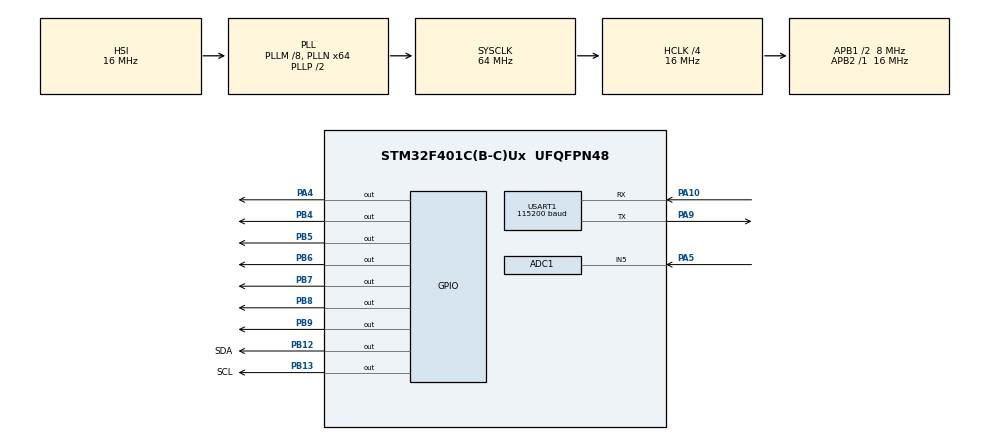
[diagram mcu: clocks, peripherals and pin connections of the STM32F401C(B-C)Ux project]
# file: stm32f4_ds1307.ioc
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ADC1.Channel-1\#ChannelRegularConversion=ADC_CHANNEL_5
ADC1.ContinuousConvMode=ENABLE
ADC1.NbrOfConversion=1
ADC1.NbrOfConversionFlag=1
ADC1.Rank-1\#ChannelRegularConversion=1
ADC1.SamplingTime-1\#ChannelRegularConversion=ADC_SAMPLETIME_3CYCLES
ADC1.ScanConvMode=ENABLE
ADC1.master=1
Dma.ADC1.0.Direction=DMA_PERIPH_TO_MEMORY
Dma.ADC1.0.FIFOMode=DMA_FIFOMODE_DISABLE
Dma.ADC1.0.Instance=DMA2_Stream0
Dma.ADC1.0.MemDataAlignment=DMA_MDATAALIGN_HALFWORD
Dma.ADC1.0.MemInc=DMA_MINC_ENABLE
Dma.ADC1.0.Mode=DMA_CIRCULAR
Dma.ADC1.0.PeriphDataAlignment=DMA_PDATAALIGN_HALFWORD
Dma.ADC1.0.PeriphInc=DMA_PINC_DISABLE
Dma.ADC1.0.Priority=DMA_PRIORITY_LOW
Dma.Request0=ADC1
Mcu.Family=STM32F4
Mcu.Name=STM32F401C(B-C)Ux
Mcu.Package=UFQFPN48
NVIC.DMA2_Stream0_IRQn=true\:0\:0\:false\:false\:true\:false\:true\:true
NVIC.PriorityGroup=NVIC_PRIORITYGROUP_4
NVIC.USART1_IRQn=true\:0\:0\:false\:false\:true\:true\:true\:true
PA10.Mode=Asynchronous
PA10.Signal=USART1_RX
PA4.GPIO_ModeDefaultOutputPP=GPIO_MODE_OUTPUT_OD
PA4.GPIO_PuPd=GPIO_PULLUP
PA4.GPIO_Speed=GPIO_SPEED_FREQ_LOW
PA4.Signal=GPIO_Output
PA5.Signal=ADCx_IN5
PA9.Mode=Asynchronous
PA9.Signal=USART1_TX
PB12.GPIO_Label=SDA
PB12.GPIO_ModeDefaultOutputPP=GPIO_MODE_OUTPUT_OD
PB12.GPIO_PuPd=GPIO_PULLUP
PB12.Signal=GPIO_Output
PB13.GPIO_Label=SCL
PB13.GPIO_PuPd=GPIO_PULLUP
PB13.Signal=GPIO_Output
PB4.Signal=GPIO_Output
PB5.Signal=GPIO_Output
PB6.Signal=GPIO_Output
PB7.Signal=GPIO_Output
PB8.Signal=GPIO_Output
PB9.Signal=GPIO_Output
PH0\ -\ OSC_IN.Mode=HSE-External-Oscillator
PH0\ -\ OSC_IN.Signal=RCC_OSC_IN
PH1\ -\ OSC_OUT.Mode=HSE-External-Oscillator
PH1\ -\ OSC_OUT.Signal=RCC_OSC_OUT
ProjectManager.HeapSize=0x200
ProjectManager.StackSize=0x400
ProjectManager.TargetToolchain=STM32CubeIDE
RCC.48MHZClocksFreq_Value=32000000
RCC.AHBCLKDivider=RCC_SYSCLK_DIV4
RCC.AHBFreq_Value=16000000
RCC.APB1CLKDivider=RCC_HCLK_DIV2
RCC.APB1Freq_Value=8000000
RCC.APB1TimFreq_Value=16000000
RCC.APB2Freq_Value=16000000
RCC.APB2TimFreq_Value=16000000
RCC.CortexFreq_Value=16000000
RCC.HCLKFreq_Value=16000000
RCC.HSE_VALUE=25000000
RCC.HSI_VALUE=16000000
RCC.LSE_VALUE=32768
RCC.PLLM=8
RCC.PLLN=64
RCC.SYSCLKFreq_VALUE=64000000
RCC.SYSCLKSource=RCC_SYSCLKSOURCE_PLLCLK
RCC.VCOOutputFreq_Value=128000000
SH.ADCx_IN5.0=ADC1_IN5,IN5
TIM1.Prescaler=15
USART1.BaudRate=115200
USART1.VirtualMode=VM_ASYNC
VP_TIM1_VS_ClockSourceINT.Mode=Internal
board=custom

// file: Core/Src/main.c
/* USER CODE BEGIN Header */
/**
  ******************************************************************************
  * @file           : main.c
  * @brief          : Main program body
  * @author         : Metehan Yenil
  * @linkedin       : https://www.linkedin.com/in/metehanyenil/
  * @github         : https://github.com/Metehan-Yenil
  ******************************************************************************
  * @attention
  *
  * Copyright (c) 2025 STMicroelectronics.
  * All rights reserved.
  *
  * This software is licensed under terms that can be found in the LICENSE file
  * in the root directory of this software component.
  * If no LICENSE file comes with this software, it is provided AS-IS.
  *
  ******************************************************************************
  */
/* USER CODE END Header */
#include "main.h"

/* USER CODE BEGIN Includes */
#include "lcd.h"
#include "ds1307.h"
#include <stdio.h>
#include <time.h>
#include <stdlib.h>  // atoi için
#include <string.h>
#include "ntc.h"
#include "ntcConfig.h"
#include "dht.h"
#include "delay.h"
/* USER CODE END Includes */

/* USER CODE BEGIN PD */
#define MAX_BUFFER_SIZE 13
/* USER CODE END PD */

ADC_HandleTypeDef hadc1;
DMA_HandleTypeDef hdma_adc1;

TIM_HandleTypeDef htim1;

UART_HandleTypeDef huart1;

/* USER CODE BEGIN PV */
uint8_t txdata[14];
uint8_t rxdata[14];
uint8_t sn,dak,saat,gun,haftagun,ay,yil;
uint16_t x=0;
uint16_t y=0;
uint8_t dataIndex = 0;
uint32_t adcData[1]; // ADC verileri için bir değişken tanımı
char uartBuffer[MAX_BUFFER_SIZE];  // UART'tan alınan veri burada saklanır
volatile uint8_t uartIndex = 0;    // UART veri indeksini takip eder
volatile uint8_t veriTamamlandi = 0; // Verinin tamamlandığını işaretler
float temperature,humidity;
uint16_t tiksay=0;
char transmitBuffer[5];
float sicaklik;

/* USER CODE END PV */

void SystemClock_Config(void);
static void MX_GPIO_Init(void);
static void MX_DMA_Init(void);
static void MX_TIM1_Init(void);
static void MX_USART1_UART_Init(void);
static void MX_ADC1_Init(void);

/* USER CODE BEGIN 0 */

void delay_us (uint16_t delay)
{
  __HAL_TIM_SET_COUNTER(&htim1, 0);
  while (__HAL_TIM_GET_COUNTER(&htim1) < delay);
}

void HAL_UART_ErrorCallback(UART_HandleTypeDef *huart) {
    if (huart->Instance == USART1) {
        clearLcd();
        writeStr(1,0,"UART Hatasi!");
        HAL_Delay(1000);

        dataIndex = 0;  // Buffer'ı sıfırla
        HAL_UART_Receive_IT(&huart1, rxdata, 1);
    }
}

void veriyiIsle()
{
    if (veriTamamlandi)
    {
        // Gelen veri formatı: "ddMMyyHHmmss"
        char tempBuffer[5]; // Geçici buffer

        // Gün
        strncpy(tempBuffer, uartBuffer, 2);
        tempBuffer[2] = '\0'; // Sonlandırıcı ekle
        gun = atoi(tempBuffer);

        // Ay
        strncpy(tempBuffer, uartBuffer + 2, 2);
        tempBuffer[2] = '\0';
        ay = atoi(tempBuffer);

        // Yıl
        strncpy(tempBuffer, uartBuffer + 4, 2);
        tempBuffer[2] = '\0';
        yil = atoi(tempBuffer);

        // Saat
        strncpy(tempBuffer, uartBuffer + 6, 2);
        tempBuffer[2] = '\0';
        saat = atoi(tempBuffer);

        // Dakika
        strncpy(tempBuffer, uartBuffer + 8, 2);
        tempBuffer[2] = '\0';
        dak = atoi(tempBuffer);

        // Saniye
        strncpy(tempBuffer, uartBuffer + 10, 2);
        tempBuffer[2] = '\0';
        sn = atoi(tempBuffer);

        SetDateTime_ds1307();

        clearLcd();
        y=veriTamamlandi;
        veriTamamlandi = 0;

    }
}

void FormatAndSendData(void) {

    char Txbuffer[24]; 					// Gönderilecek veri için buffer
    HAL_StatusTypeDef status;

    GetDateTime_ds1307();
    DHT_GetData(); 						// DHT22 sıcaklık ve nem bilgisi al

    snprintf(Txbuffer, sizeof(Txbuffer), "<%.2f %.2f %.2f %02d:%02d:%02d %02d;%02d;%02d>",
    		 sicaklik, 	  // NTC Sıcaklık
			 temperature,        // DHT sıcaklık
             humidity,          // DHT nem
             saat,        // Saat
             dak,    // Dakika
             sn,   // Saniye
             gun,      // Gün
             ay,   // Ay
             yil);  // Yıl

    status = HAL_UART_Transmit(&huart1, (uint8_t*)Txbuffer, strlen(Txbuffer), 100);
    if (status != HAL_OK) {

        char error_msg[] = "USART transmit error!\r\n";
        HAL_UART_Transmit(&huart1, (uint8_t*)error_msg, strlen(error_msg), 100);
        clearLcd();
        writeStr(1,0,"transmit error");
        HAL_Delay(2000);
    }
}

/* USER CODE END 0 */

int main(void)
{

  /* MCU Configuration--------------------------------------------------------*/

  /* Reset of all peripherals, Initializes the Flash interface and the Systick. */
  HAL_Init();

  /* Configure the system clock */
  SystemClock_Config();

  /* Initialize all configured peripherals */
  MX_GPIO_Init();
  MX_DMA_Init();
  MX_TIM1_Init();
  MX_USART1_UART_Init();
  MX_ADC1_Init();
  /* USER CODE BEGIN 2 */
      HAL_TIM_Base_Start(&htim1);

       lcdInit();
       writeStr(1,0,"SISTEM          ");
       writeStr(2,0,"BASLIYOR        ");
       HAL_Delay(2000);
       clearLcd();
       //HAL_UART_Receive_IT(&huart1, rxdata, 1);
                  if(HAL_UART_Receive_IT(&huart1, rxdata, 1) != HAL_OK)
                  {
                      writeStr(1,0,"UART Hata!");
                      HAL_Delay(1000);

                  }
                  else
                  {
                      writeStr(1,0,"UART Hazir");
                      writeStr(2,0,"Veri Bekliyor");
                      HAL_Delay(1000);
                      clearLcd();
                  }

       //saat=01; dak=59; sn=55;
      //SetDateTime_ds1307();
  /* USER CODE END 2 */

  /* Infinite loop */
  /* USER CODE BEGIN WHILE */
  while (1)
  {
	  if(tiksay>=2000){
	  		  tiksay=0;
	  		  DHT_GetData();
	  	  	  writeStr(2,9,"rh");
	  	  	  displayFloat(2,11, humidity);
	  	  	  writeStr(2,13,"T");
	  	  	  displayFloat(2, 14,temperature);

	  }
    HAL_ADC_Start_DMA(&hadc1, (uint32_t*)adcData, 1);

    veriyiIsle();
    GetDateTime_ds1307();
    displayInt(1,0,saat);
    writeStr(1,2,":");
    displayInt(1,3,dak);
    writeStr(1,5,":");
    displayInt(1,6,sn);

    displayInt(2,0,gun);
    writeStr(2,2,"/");
    displayInt(2,3,ay);
    writeStr(2,5,"/");
    displayInt(2,6,yil);
    writeStr(1,9,"A:");displayInt(1,11,ntc_convertToC(adcData[0]));writeStr(1,13,"C");

    	sicaklik = ntc_convertToC(adcData[0]);
       /* sprintf(transmitBuffer, "%d\n", sicaklik);
        HAL_UART_Transmit(&huart1, (uint8_t*)transmitBuffer, strlen(transmitBuffer), 100);
    delay_us(1000);
    x++;*/
    FormatAndSendData();
    //HAL_Delay(1000);
    /* USER CODE END WHILE */

  }
}

void SystemClock_Config(void)
{
  RCC_OscInitTypeDef RCC_OscInitStruct = {0};
  RCC_ClkInitTypeDef RCC_ClkInitStruct = {0};

  /** Configure the main internal regulator output voltage
  */
  __HAL_RCC_PWR_CLK_ENABLE();
  __HAL_PWR_VOLTAGESCALING_CONFIG(PWR_REGULATOR_VOLTAGE_SCALE2);

  /** Initializes the RCC Oscillators according to the specified parameters
  * in the RCC_OscInitTypeDef structure.
  */
  RCC_OscInitStruct.OscillatorType = RCC_OSCILLATORTYPE_HSI;
  RCC_OscInitStruct.HSIState = RCC_HSI_ON;
  RCC_OscInitStruct.HSICalibrationValue = RCC_HSICALIBRATION_DEFAULT;
  RCC_OscInitStruct.PLL.PLLState = RCC_PLL_ON;
  RCC_OscInitStruct.PLL.PLLSource = RCC_PLLSOURCE_HSI;
  RCC_OscInitStruct.PLL.PLLM = 8;
  RCC_OscInitStruct.PLL.PLLN = 64;
  RCC_OscInitStruct.PLL.PLLP = RCC_PLLP_DIV2;
  RCC_OscInitStruct.PLL.PLLQ = 4;
  if (HAL_RCC_OscConfig(&RCC_OscInitStruct) != HAL_OK)
  {
    Error_Handler();
  }

  /** Initializes the CPU, AHB and APB buses clocks
  */
  RCC_ClkInitStruct.ClockType = RCC_CLOCKTYPE_HCLK|RCC_CLOCKTYPE_SYSCLK
                              |RCC_CLOCKTYPE_PCLK1|RCC_CLOCKTYPE_PCLK2;
  RCC_ClkInitStruct.SYSCLKSource = RCC_SYSCLKSOURCE_PLLCLK;
  RCC_ClkInitStruct.AHBCLKDivider = RCC_SYSCLK_DIV4;
  RCC_ClkInitStruct.APB1CLKDivider = RCC_HCLK_DIV2;
  RCC_ClkInitStruct.APB2CLKDivider = RCC_HCLK_DIV1;

  if (HAL_RCC_ClockConfig(&RCC_ClkInitStruct, FLASH_LATENCY_0) != HAL_OK)
  {
    Error_Handler();
  }
}

static void MX_ADC1_Init(void)
{

  ADC_ChannelConfTypeDef sConfig = {0};

  /** Configure the global features of the ADC (Clock, Resolution, Data Alignment and number of conversion)
  */
  hadc1.Instance = ADC1;
  hadc1.Init.ClockPrescaler = ADC_CLOCK_SYNC_PCLK_DIV2;
  hadc1.Init.Resolution = ADC_RESOLUTION_12B;
  hadc1.Init.ScanConvMode = ENABLE;
  hadc1.Init.ContinuousConvMode = ENABLE;
  hadc1.Init.DiscontinuousConvMode = DISABLE;
  hadc1.Init.ExternalTrigConvEdge = ADC_EXTERNALTRIGCONVEDGE_NONE;
  hadc1.Init.ExternalTrigConv = ADC_SOFTWARE_START;
  hadc1.Init.DataAlign = ADC_DATAALIGN_RIGHT;
  hadc1.Init.NbrOfConversion = 1;
  hadc1.Init.DMAContinuousRequests = DISABLE;
  hadc1.Init.EOCSelection = ADC_EOC_SINGLE_CONV;
  if (HAL_ADC_Init(&hadc1) != HAL_OK)
  {
    Error_Handler();
  }

  /** Configure for the selected ADC regular channel its corresponding rank in the sequencer and its sample time.
  */
  sConfig.Channel = ADC_CHANNEL_5;
  sConfig.Rank = 1;
  sConfig.SamplingTime = ADC_SAMPLETIME_3CYCLES;
  if (HAL_ADC_ConfigChannel(&hadc1, &sConfig) != HAL_OK)
  {
    Error_Handler();
  }

}

static void MX_TIM1_Init(void)
{

  TIM_ClockConfigTypeDef sClockSourceConfig = {0};
  TIM_MasterConfigTypeDef sMasterConfig = {0};

  htim1.Instance = TIM1;
  htim1.Init.Prescaler = 15;
  htim1.Init.CounterMode = TIM_COUNTERMODE_UP;
  htim1.Init.Period = 65535;
  htim1.Init.ClockDivision = TIM_CLOCKDIVISION_DIV1;
  htim1.Init.RepetitionCounter = 0;
  htim1.Init.AutoReloadPreload = TIM_AUTORELOAD_PRELOAD_DISABLE;
  if (HAL_TIM_Base_Init(&htim1) != HAL_OK)
  {
    Error_Handler();
  }
  sClockSourceConfig.ClockSource = TIM_CLOCKSOURCE_INTERNAL;
  if (HAL_TIM_ConfigClockSource(&htim1, &sClockSourceConfig) != HAL_OK)
  {
    Error_Handler();
  }
  sMasterConfig.MasterOutputTrigger = TIM_TRGO_RESET;
  sMasterConfig.MasterSlaveMode = TIM_MASTERSLAVEMODE_DISABLE;
  if (HAL_TIMEx_MasterConfigSynchronization(&htim1, &sMasterConfig) != HAL_OK)
  {
    Error_Handler();
  }

}

static void MX_USART1_UART_Init(void)
{

  huart1.Instance = USART1;
  huart1.Init.BaudRate = 9600;
  huart1.Init.WordLength = UART_WORDLENGTH_8B;
  huart1.Init.StopBits = UART_STOPBITS_1;
  huart1.Init.Parity = UART_PARITY_NONE;
  huart1.Init.Mode = UART_MODE_TX_RX;
  huart1.Init.HwFlowCtl = UART_HWCONTROL_NONE;
  huart1.Init.OverSampling = UART_OVERSAMPLING_16;
  if (HAL_UART_Init(&huart1) != HAL_OK)
  {
    Error_Handler();
  }

}

static void MX_DMA_Init(void)
{

  /* DMA controller clock enable */
  __HAL_RCC_DMA2_CLK_ENABLE();

  /* DMA interrupt init */
  /* DMA2_Stream0_IRQn interrupt configuration */
  HAL_NVIC_SetPriority(DMA2_Stream0_IRQn, 0, 0);
  HAL_NVIC_EnableIRQ(DMA2_Stream0_IRQn);

}

static void MX_GPIO_Init(void)
{
  GPIO_InitTypeDef GPIO_InitStruct = {0};

  /* GPIO Ports Clock Enable */
  __HAL_RCC_GPIOH_CLK_ENABLE();
  __HAL_RCC_GPIOA_CLK_ENABLE();
  __HAL_RCC_GPIOB_CLK_ENABLE();

  /*Configure GPIO pin Output Level */
  HAL_GPIO_WritePin(GPIOA, GPIO_PIN_4, GPIO_PIN_RESET);

  /*Configure GPIO pin Output Level */
  HAL_GPIO_WritePin(GPIOB, GPIO_PIN_10|SDA_Pin|SCL_Pin|GPIO_PIN_4
                          |GPIO_PIN_5|GPIO_PIN_6|GPIO_PIN_7|GPIO_PIN_8
                          |GPIO_PIN_9, GPIO_PIN_RESET);

  /*Configure GPIO pin : PA4 */
  GPIO_InitStruct.Pin = GPIO_PIN_4;
  GPIO_InitStruct.Mode = GPIO_MODE_OUTPUT_OD;
  GPIO_InitStruct.Pull = GPIO_PULLUP;
  GPIO_InitStruct.Speed = GPIO_SPEED_FREQ_LOW;
  HAL_GPIO_Init(GPIOA, &GPIO_InitStruct);

  /*Configure GPIO pins : PB10 PB4 PB5 PB6
                           PB7 PB8 PB9 */
  GPIO_InitStruct.Pin = GPIO_PIN_10|GPIO_PIN_4|GPIO_PIN_5|GPIO_PIN_6
                          |GPIO_PIN_7|GPIO_PIN_8|GPIO_PIN_9;
  GPIO_InitStruct.Mode = GPIO_MODE_OUTPUT_PP;
  GPIO_InitStruct.Pull = GPIO_NOPULL;
  GPIO_InitStruct.Speed = GPIO_SPEED_FREQ_LOW;
  HAL_GPIO_Init(GPIOB, &GPIO_InitStruct);

  /*Configure GPIO pin : SDA_Pin */
  GPIO_InitStruct.Pin = SDA_Pin;
  GPIO_InitStruct.Mode = GPIO_MODE_OUTPUT_OD;
  GPIO_InitStruct.Pull = GPIO_PULLUP;
  GPIO_InitStruct.Speed = GPIO_SPEED_FREQ_LOW;
  HAL_GPIO_Init(SDA_GPIO_Port, &GPIO_InitStruct);

  /*Configure GPIO pin : SCL_Pin */
  GPIO_InitStruct.Pin = SCL_Pin;
  GPIO_InitStruct.Mode = GPIO_MODE_OUTPUT_PP;
  GPIO_InitStruct.Pull = GPIO_PULLUP;
  GPIO_InitStruct.Speed = GPIO_SPEED_FREQ_LOW;
  HAL_GPIO_Init(SCL_GPIO_Port, &GPIO_InitStruct);

}

/* USER CODE BEGIN 4 */
void HAL_UART_RxCpltCallback(UART_HandleTypeDef *huart) {
    if (huart->Instance == USART1) {
        uartBuffer[uartIndex++] = rxdata[0];  // Gelen baytı buffer'a ekle
        if (uartIndex >= MAX_BUFFER_SIZE || rxdata[0] == '\n') {
            veriTamamlandi = 1;
            uartBuffer[uartIndex] = '\0';
            uartIndex = 0;
        }
        HAL_UART_Receive_IT(&huart1, rxdata, 1);
    }
}

/* USER CODE END 4 */

void Error_Handler(void)
{
  __disable_irq();
  while (1)
  {
  }
}
